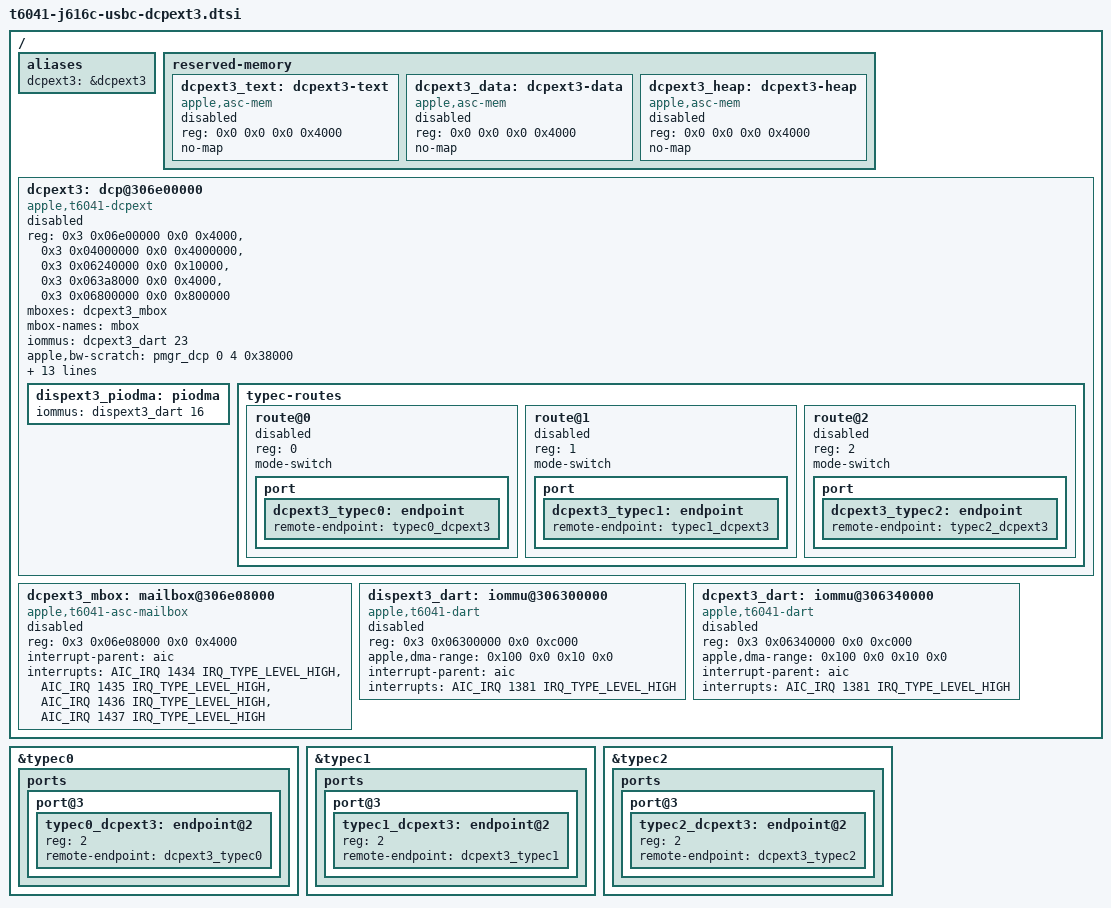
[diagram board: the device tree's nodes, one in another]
// SPDX-License-Identifier: GPL-2.0+ OR MIT
/*
 * A third USB-C DisplayPort processor on the J614c and J616c: dcpext3, with
 * a route to each of the three USB-C ports (typec0-2), next to dcpext1 and
 * dcpext2. Each USB-C port can then drive a display of its own.
 *
 * dcpext3 is dcpext2's block moved from 0x6xxxxxxxx to 0x3xxxxxxxx (ADT
 * /arm-io/dcpext3 at 0x106e00000 + 0x2_0000_0000, interrupts +0x48,
 * external-index 4). iBoot preloads and starts it on the M4 Max
 * (iop-dcpext3-nub pre-loaded 1, running 1). As dcpext1 and dcpext2 on this
 * SoC, no PMP and no DISPEXT3 power domain is described.
 *
 * Everything here is disabled. The boot loader fills dcpext3's firmware
 * memory from this boot's ADT (aura t6041_exts) and the display gate enables
 * the chain once it has.
 */

/ {
	aliases {
		dcpext3 = &dcpext3;
	};

	reserved-memory {
		dcpext3_text: dcpext3-text {
			compatible = "apple,asc-mem";
			reg = <0x0 0x0 0x0 0x4000>;
			no-map;
			status = "disabled";
		};

		dcpext3_data: dcpext3-data {
			compatible = "apple,asc-mem";
			reg = <0x0 0x0 0x0 0x4000>;
			no-map;
			status = "disabled";
		};

		dcpext3_heap: dcpext3-heap {
			compatible = "apple,asc-mem";
			reg = <0x0 0x0 0x0 0x4000>;
			no-map;
			status = "disabled";
		};
	};

	dcpext3: dcp@306e00000 {
		compatible = "apple,t6041-dcpext", "apple,dcpext";
		reg = <0x3 0x06e00000 0x0 0x4000>,
		      <0x3 0x04000000 0x0 0x4000000>,
		      <0x3 0x06240000 0x0 0x10000>,
		      <0x3 0x063a8000 0x0 0x4000>,
		      <0x3 0x06800000 0x0 0x800000>;
		reg-names = "coproc", "disp-0", "disp-1", "disp-2", "disp-3";
		mboxes = <&dcpext3_mbox>;
		mbox-names = "mbox";
		iommus = <&dcpext3_dart 23>;
		/*
		 * PMGR bandwidth agent scratch: the bwr-agent the ADT dispext3
		 * function-bw_req_interrupt0 (0x4f) names: ADT
		 * pmgr bwr-agent DISP_EXT3, slot 6, so 0x20000 + 6 * 0x4000.
		 */
		apple,bw-scratch = <&pmgr_dcp 0 4 0x38000>;
		/* ADT iop-dcpext3-nub external-index */
		apple,dcp-endpoint = <4>;
		/* as dcpext0/1: without it apple-dcp's probe fails with -EINVAL */
		apple,iomfb-surfaces = <1 1 0 0>;
		apple,connector-type = "USB-C";
		phys = <&atcphy0 PHY_TYPE_DP>, <&atcphy1 PHY_TYPE_DP>, <&atcphy2 PHY_TYPE_DP>;
		phy-names = "typec0", "typec1", "typec2";
		mux-controls = <&atcphy0_xbar 0>, <&atcphy1_xbar 0>, <&atcphy2_xbar 0>;
		mux-control-names = "typec0", "typec1", "typec2";
		/*
		 * indexed by route; crossbar state = 2 * dp-switch-ufp-endpoint
		 * (3) + port (0)
		 */
		apple,typec-dptx-phys = <0 1 2>;
		apple,typec-mux-indices = <6 6 6>;
		memory-region = <&dcpext3_text>, <&dcpext3_data>, <&dcpext3_heap>;
		memory-region-names = "text", "data", "heap";
		status = "disabled";

		dispext3_piodma: piodma {
			iommus = <&dispext3_dart 16>;
		};

		typec-routes {
			#address-cells = <1>;
			#size-cells = <0>;

			route@0 {
				reg = <0>;
				mode-switch;
				status = "disabled";

				port {
					dcpext3_typec0: endpoint {
						remote-endpoint = <&typec0_dcpext3>;
					};
				};
			};

			route@1 {
				reg = <1>;
				mode-switch;
				status = "disabled";

				port {
					dcpext3_typec1: endpoint {
						remote-endpoint = <&typec1_dcpext3>;
					};
				};
			};

			route@2 {
				reg = <2>;
				mode-switch;
				status = "disabled";

				port {
					dcpext3_typec2: endpoint {
						remote-endpoint = <&typec2_dcpext3>;
					};
				};
			};
		};
	};

	dcpext3_mbox: mailbox@306e08000 {
		compatible = "apple,t6041-asc-mailbox", "apple,asc-mailbox-v4";
		reg = <0x3 0x06e08000 0x0 0x4000>;
		interrupt-parent = <&aic>;
		interrupts = <AIC_IRQ 1434 IRQ_TYPE_LEVEL_HIGH>,
			     <AIC_IRQ 1435 IRQ_TYPE_LEVEL_HIGH>,
			     <AIC_IRQ 1436 IRQ_TYPE_LEVEL_HIGH>,
			     <AIC_IRQ 1437 IRQ_TYPE_LEVEL_HIGH>;
		interrupt-names = "send-empty", "send-not-empty",
				  "recv-empty", "recv-not-empty";
		#mbox-cells = <0>;
		status = "disabled";
	};

	dispext3_dart: iommu@306300000 {
		compatible = "apple,t6041-dart", "apple,t8110-dart";
		reg = <0x3 0x06300000 0x0 0xc000>;
		#iommu-cells = <1>;
		apple,dma-range = <0x100 0x0 0x10 0x0>;
		interrupt-parent = <&aic>;
		interrupts = <AIC_IRQ 1381 IRQ_TYPE_LEVEL_HIGH>;
		status = "disabled";
	};

	dcpext3_dart: iommu@306340000 {
		compatible = "apple,t6041-dart", "apple,t8110-dart";
		reg = <0x3 0x06340000 0x0 0xc000>;
		#iommu-cells = <1>;
		apple,dma-range = <0x100 0x0 0x10 0x0>;
		interrupt-parent = <&aic>;
		interrupts = <AIC_IRQ 1381 IRQ_TYPE_LEVEL_HIGH>;
		status = "disabled";
	};
};

&typec0 {
	ports {
		port@3 {
			typec0_dcpext3: endpoint@2 {
				reg = <2>;
				remote-endpoint = <&dcpext3_typec0>;
			};
		};
	};
};

&typec1 {
	ports {
		port@3 {
			typec1_dcpext3: endpoint@2 {
				reg = <2>;
				remote-endpoint = <&dcpext3_typec1>;
			};
		};
	};
};

&typec2 {
	ports {
		port@3 {
			typec2_dcpext3: endpoint@2 {
				reg = <2>;
				remote-endpoint = <&dcpext3_typec2>;
			};
		};
	};
};
